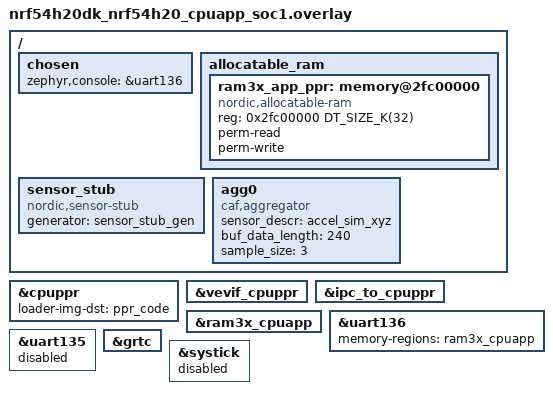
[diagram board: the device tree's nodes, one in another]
/*
 * Copyright (c) 2022 Nordic Semiconductor ASA
 *
 * SPDX-License-Identifier: LicenseRef-Nordic-5-Clause
 */

/ {
	chosen {
		zephyr,console = &uart136;
	};

	allocatable_ram {
		#address-cells = <1>;
		#size-cells = <1>;

		/* Configure RAM3x region.
		 * This is done to ensure correct UICR generation.
		 */
		ram3x_app_ppr: memory@2fc00000 {
			compatible = "nordic,allocatable-ram";
			reg = <0x2fc00000 DT_SIZE_K(32)>;
			perm-read;
			perm-write;
		};
	};

	sensor_stub: sensor_stub {
		compatible = "nordic,sensor-stub";
		generator = "sensor_stub_gen";
		status = "okay";
	};

	agg0: agg0 {
		compatible = "caf,aggregator";
		sensor_descr = "accel_sim_xyz";
		buf_data_length = <240>;
		sample_size = <3>;
		status = "okay";
	};
};

&cpuppr {
	loader-img-dst = <&ppr_code>;
	status = "okay";
};

&vevif_cpuppr {
	status = "okay";
};

ipc0: &ipc_to_cpuppr {
	status = "okay";
};

&ram3x_cpuapp {
	status = "okay";
};

&uart136 {
	status = "okay";
	memory-regions = <&ram3x_cpuapp>;
};

&uart135 {
	status = "reserved";
};

&grtc {
	status = "okay";
};

&systick {
	status = "disabled";
};
